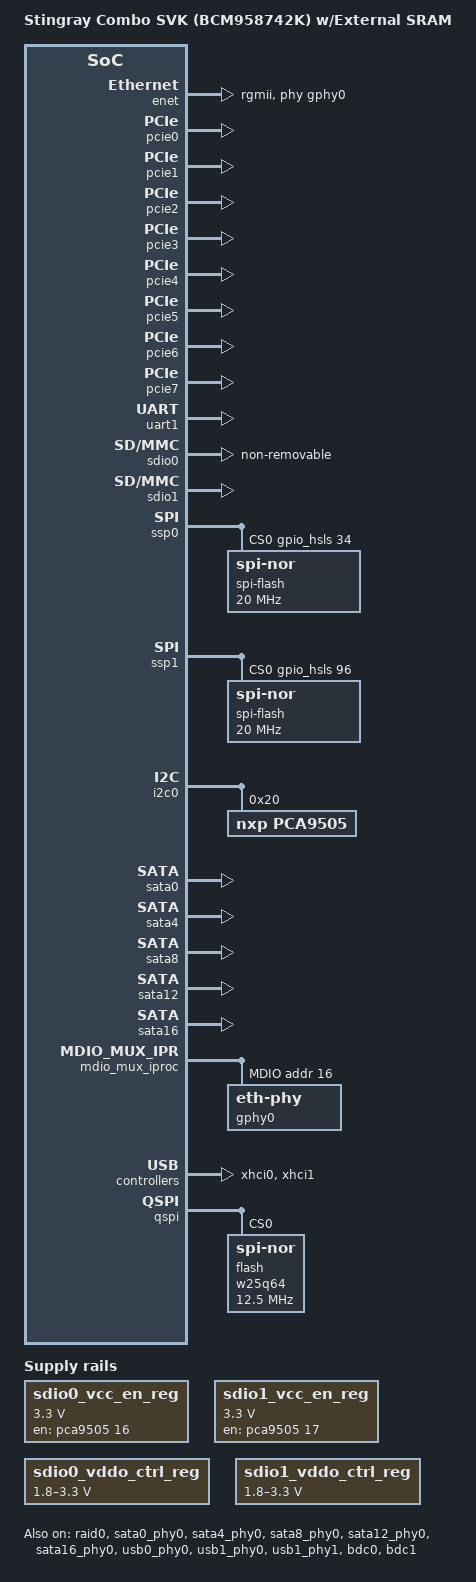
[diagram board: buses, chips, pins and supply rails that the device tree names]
/*
 *  BSD LICENSE
 *
 *  Copyright(c) 2016 Broadcom.  All rights reserved.
 *
 *  Redistribution and use in source and binary forms, with or without
 *  modification, are permitted provided that the following conditions
 *  are met:
 *
 *    * Redistributions of source code must retain the above copyright
 *      notice, this list of conditions and the following disclaimer.
 *    * Redistributions in binary form must reproduce the above copyright
 *      notice, this list of conditions and the following disclaimer in
 *      the documentation and/or other materials provided with the
 *      distribution.
 *    * Neither the name of Broadcom Corporation nor the names of its
 *      contributors may be used to endorse or promote products derived
 *      from this software without specific prior written permission.
 *
 *  THIS SOFTWARE IS PROVIDED BY THE COPYRIGHT HOLDERS AND CONTRIBUTORS
 *  "AS IS" AND ANY EXPRESS OR IMPLIED WARRANTIES, INCLUDING, BUT NOT
 *  LIMITED TO, THE IMPLIED WARRANTIES OF MERCHANTABILITY AND FITNESS FOR
 *  A PARTICULAR PURPOSE ARE DISCLAIMED. IN NO EVENT SHALL THE COPYRIGHT
 *  OWNER OR CONTRIBUTORS BE LIABLE FOR ANY DIRECT, INDIRECT, INCIDENTAL,
 *  SPECIAL, EXEMPLARY, OR CONSEQUENTIAL DAMAGES (INCLUDING, BUT NOT
 *  LIMITED TO, PROCUREMENT OF SUBSTITUTE GOODS OR SERVICES; LOSS OF USE,
 *  DATA, OR PROFITS; OR BUSINESS INTERRUPTION) HOWEVER CAUSED AND ON ANY
 *  THEORY OF LIABILITY, WHETHER IN CONTRACT, STRICT LIABILITY, OR TORT
 *  (INCLUDING NEGLIGENCE OR OTHERWISE) ARISING IN ANY WAY OUT OF THE USE
 * OF THIS SOFTWARE, EVEN IF ADVISED OF THE POSSIBILITY OF SUCH DAMAGE.
 */

/dts-v1/;

/* HACK: Reserve initrd location
 * The memreserve entry for initrd is supposed
 * to be updated in DTB by bootloader before
 * handing over DTB to Linux kernel.
 */
/memreserve/ 0x75000000 0x00800000;
/* HACK: Reserve bl31 location
 * The memreserve entry for bl31 is supposed to
 * be updated in DTB by bootloader before handing
 * over DTB to Linux kernel. This is so because
 * only firmware (or bootloader) know the correct
 * location of bl31 and bl31 location can also
 * change in-future.
 */
/memreserve/ 0x77f00000 0x00100000;

#include "stingray.dtsi"
#include <dt-bindings/gpio/gpio.h>

/ {
	model = "Stingray Combo SVK (BCM958742K) w/External SRAM";

	chosen { /* HACK: hard-code kernel args and initrd location */
		bootargs = "root=/dev/ram rw console=ttyS0,115200n8 \
			    earlycon=uart8250,mmio32,0x68a10000 cma=8M maxcpus=2";
		linux,initrd-start = <0x0 0x75000000>;
		linux,initrd-end = <0x0 0x75800000>;
	};

	reserved-memory {
		#address-cells = <2>;
		#size-cells = <2>;
		ranges;

		amac_reserved: amacdma@66d10000 {
			compatible = "shared-dma-pool";
			reg = <0x00000000 0x66d10000 0x0 0x20000>;
			no-map;
		};
	};

	sdio0_vcc_en_reg: sdio0_en {
		compatible = "regulator-fixed";
		regulator-name = "sdio0_vcc_en-reg";
		regulator-min-microvolt = <3300000>;
		regulator-max-microvolt = <3300000>;
		gpio = <&pca9505 16 0>;
		enable-active-high;
	};

	sdio1_vcc_en_reg: sdio1_en {
		compatible = "regulator-fixed";
		regulator-name = "sdio1_vcc_en-reg";
		regulator-min-microvolt = <3300000>;
		regulator-max-microvolt = <3300000>;
		gpio = <&pca9505 17 0>;
		enable-active-high;
	};

	sdio0_vddo_ctrl_reg: sdio0_vddo_ctrl {
		compatible = "regulator-gpio";
		regulator-name = "sdio0_vddo_ctrl_reg";
		regulator-type = "voltage";
		regulator-min-microvolt = <1800000>;
		regulator-max-microvolt = <3300000>;
		gpios = <&pca9505 18 0>;
		states = <3300000 0x0
			  1800000 0x1>;
	};

	sdio1_vddo_ctrl_reg: sdio1_vddo_ctrl {
		compatible = "regulator-gpio";
		regulator-name = "sdio1_vddo_ctrl_reg";
		regulator-type = "voltage";
		regulator-min-microvolt = <1800000>;
		regulator-max-microvolt = <3300000>;
		gpios = <&pca9505 19 0>;
		states = <3300000 0x0
			  1800000 0x1>;
	};
};

&memory {
	reg = <0x00000000 0x74000000 0x0 0x04000000>; /* 64MB */
};

&enet {
	compatible = "brcm,amac-enet-extsram";
	phy-mode = "rgmii";
	max-speed = <1000>;
	phy-handle = <&gphy0>;
	memory-region = <&amac_reserved>;
	brcm,enet-phy-lswap;
	status = "okay";
};

&pcie0 {
	dma-ranges = <0x43000000 0x00 0x74000000 0x00 0x74000000 0x00 0x4000000>;
	/delete-property/ dma-coherent;
	status = "okay";
};

&pcie1 {
	dma-ranges = <0x43000000 0x00 0x74000000 0x00 0x74000000 0x00 0x4000000>;
	/delete-property/ dma-coherent;
	status = "okay";
};

&pcie2 {
	dma-ranges = <0x43000000 0x00 0x74000000 0x00 0x74000000 0x00 0x4000000>;
	/delete-property/ dma-coherent;
	status = "okay";
};

&pcie3 {
	dma-ranges = <0x43000000 0x00 0x74000000 0x00 0x74000000 0x00 0x4000000>;
	/delete-property/ dma-coherent;
	status = "okay";
};

&pcie4 {
	dma-ranges = <0x43000000 0x00 0x74000000 0x00 0x74000000 0x00 0x4000000>;
	/delete-property/ dma-coherent;
	status = "okay";
};

&pcie5 {
	dma-ranges = <0x43000000 0x00 0x74000000 0x00 0x74000000 0x00 0x4000000>;
	/delete-property/ dma-coherent;
	status = "okay";
};

&pcie6 {
	dma-ranges = <0x43000000 0x00 0x74000000 0x00 0x74000000 0x00 0x4000000>;
	/delete-property/ dma-coherent;
	status = "okay";
};

&pcie7 {
	dma-ranges = <0x43000000 0x00 0x74000000 0x00 0x74000000 0x00 0x4000000>;
	/delete-property/ dma-coherent;
	status = "okay";
};

&uart1 {
	status = "okay";
};

&sdio0 {
	non-removable;
	dsr;
	status = "okay";
};

&sdio1 {
	dsr;
	status = "okay";
};

&raid_mbox {
	/* Use only one ring to save memory */
	reg = <0x67400000 0x10000>;
	/delete-property/ dma-coherent;
	status = "okay";
};

&raid0 {
	/* Use only one ring to save memory */
	mboxes = <&raid_mbox 0 0x1 0xff00>;
	status = "okay";
};

&ssp0 {
	pinctrl-0 = <&spi0_pins>;
	cs-gpios = <&gpio_hsls 34 0>;
	status = "okay";

	spi-flash@0 {
		compatible = "jedec,spi-nor";
		reg = <0>;
		spi-max-frequency = <20000000>;
	};
};

&ssp1 {
	pinctrl-0 = <&spi1_pins>;
	cs-gpios = <&gpio_hsls 96 0>;
	status = "okay";

	spi-flash@0 {
		compatible = "jedec,spi-nor";
		reg = <0>;
		spi-max-frequency = <20000000>;
	};
};

&i2c0 {
	status = "okay";

	pca9505: pca9505@20 {
		compatible = "nxp,pca9505";
		gpio-controller;
		#gpio-cells = <2>;
		reg = <0x20>;
	};
};

&sata0_phy0 {
	status = "okay";
};

&sata0 {
	status = "okay";
};

&sata4_phy0 {
	status = "okay";
};

&sata4 {
	status = "okay";
};

&sata8_phy0 {
	status = "okay";
};

&sata8 {
	status = "okay";
};

&sata12_phy0 {
	status = "okay";
};

&sata12 {
	status = "okay";
};

&sata16_phy0 {
	status = "okay";
};

&sata16 {
	status = "okay";
};

&mdio_mux_iproc {
	mdio@10 {
		gphy0: eth-phy@10 {
			reg = <0x10>;
		};
	};
};

&usb0_phy0 {
	status = "okay";
};

&usb1_phy0 {
	status = "okay";
};

&usb1_phy1 {
	status = "okay";
};

&xhci0 {
	status = "okay";
};

&xhci1 {
	status = "okay";
};

&bdc0 {
	status = "okay";
};

&bdc1 {
	status = "okay";
};

&qspi {
	pinctrl-names = "default";
	pinctrl-0 = <&qspi_pins>;
	bspi-sel = <0>;
	status = "okay";

	flash: w25q64@0 {
		#address-cells = <1>;
		#size-cells = <1>;
		compatible = "jedec,spi-nor";
		reg = <0x0>;
		spi-max-frequency = <12500000>;
	};
};
